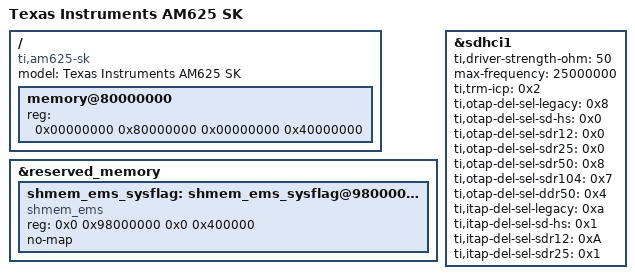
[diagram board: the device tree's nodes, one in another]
// SPDX-License-Identifier: GPL-2.0-only OR MIT
/*
 * AM625 SK: https://www.ti.com/lit/zip/sprr448
 *
 * Copyright (C) 2021-2024 Texas Instruments Incorporated - https://www.ti.com/
 */

/dts-v1/;

#include "k3-am625.dtsi"
#include "k3-am625-sk-common.dtsi"

/ {
	compatible = "ti,am625-sk", "ti,am625";
	model = "Texas Instruments AM625 SK";

	memory@80000000 {
		/* 2G RAM */
		reg = <0x00000000 0x80000000 0x00000000 0x40000000>;
		device_type = "memory";
		bootph-pre-ram;
	};
};

&reserved_memory {
	/* 该共享内存用于spl启动到kernel之间的信息传递 */
	shmem_ems_sysflag: shmem_ems_sysflag@98000000 {
		compatible = "shmem_ems";
		reg = <0x0 0x98000000 0x0 0x400000>; /* 4MB */
		no-map;
	};
};

/* Match SDK configuration for SD card - more conservative timing */
&sdhci1 {
	ti,driver-strength-ohm = <50>;
	max-frequency = <25000000>;
	ti,trm-icp = <0x2>;
	ti,otap-del-sel-legacy = <0x8>;
	ti,otap-del-sel-sd-hs = <0x0>;
	ti,otap-del-sel-sdr12 = <0x0>;
	ti,otap-del-sel-sdr25 = <0x0>;
	ti,otap-del-sel-sdr50 = <0x8>;
	ti,otap-del-sel-sdr104 = <0x7>;
	ti,otap-del-sel-ddr50 = <0x4>;
	ti,itap-del-sel-legacy = <0xa>;
	ti,itap-del-sel-sd-hs = <0x1>;
	ti,itap-del-sel-sdr12 = <0xA>;
	ti,itap-del-sel-sdr25 = <0x1>;
};
